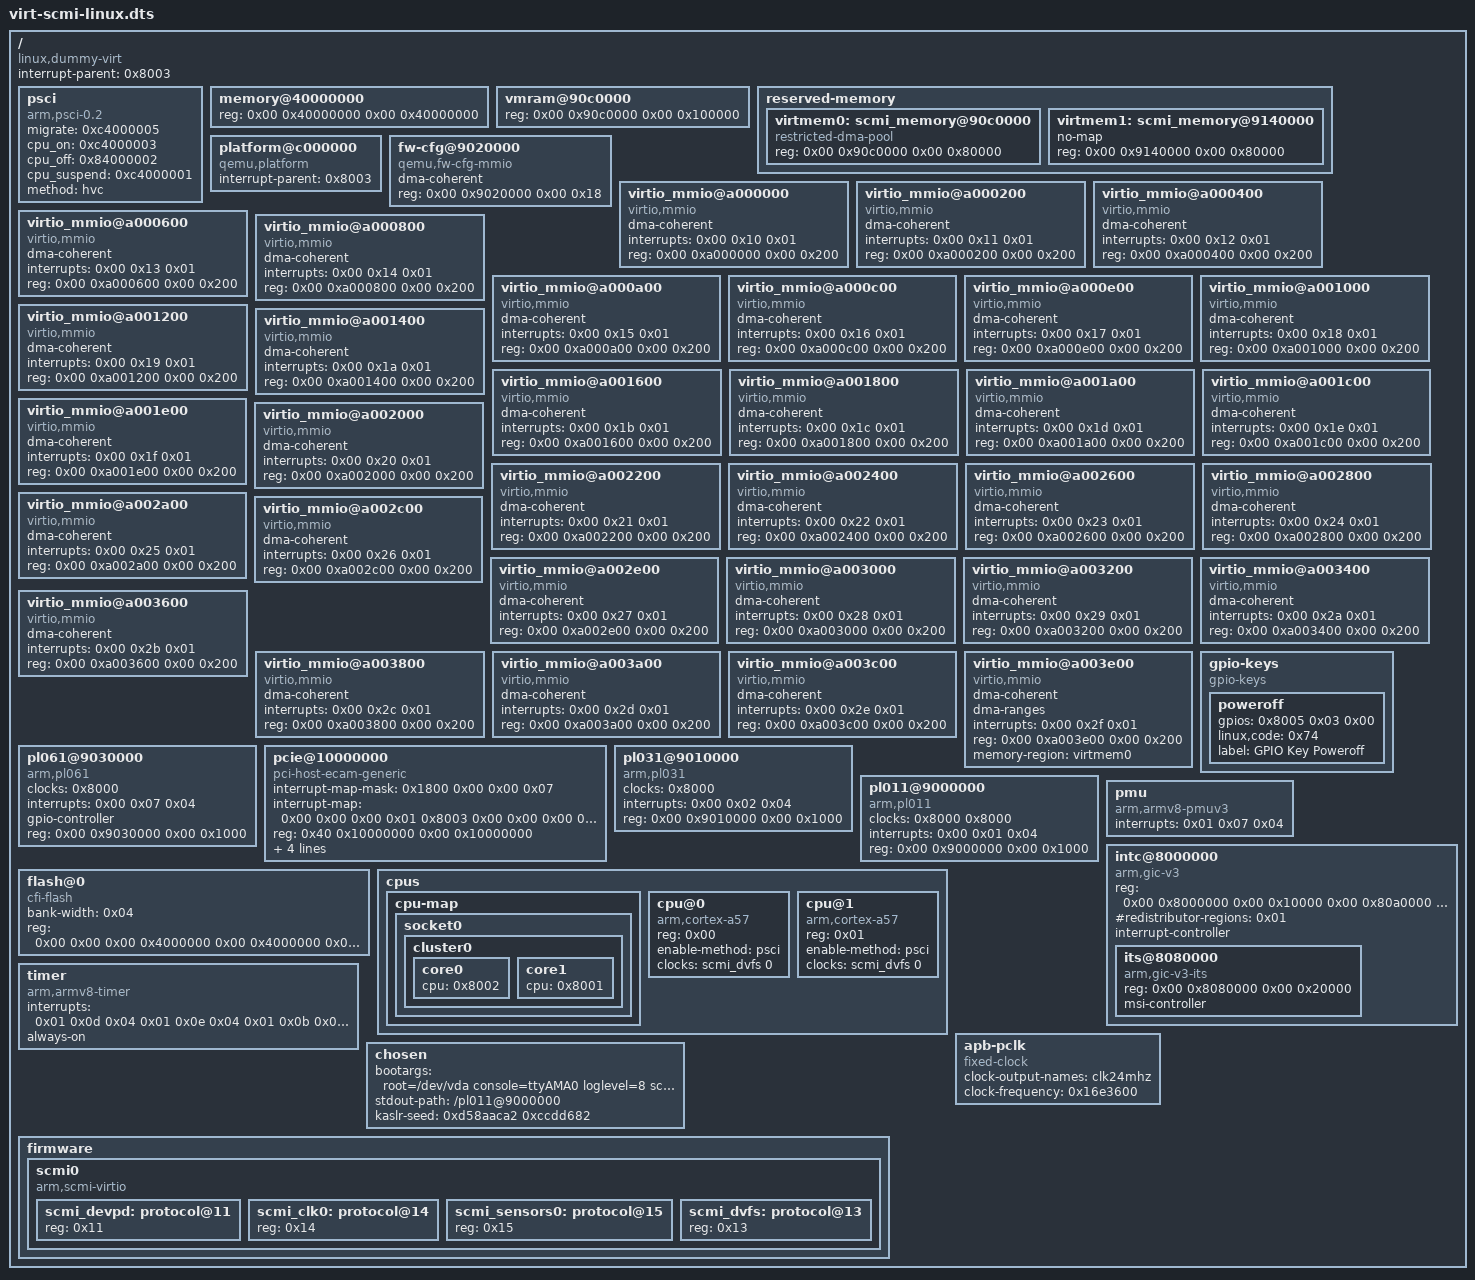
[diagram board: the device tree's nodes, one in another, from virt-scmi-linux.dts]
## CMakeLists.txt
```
# SPDX-License-Identifier: Apache-2.0

cmake_minimum_required(VERSION 3.13.1)

find_package(Zephyr REQUIRED HINTS $ENV{ZEPHYR_BASE})

target_sources(app PRIVATE src/main.c)

target_link_libraries(app PRIVATE arch-zephyr)

add_subdirectory("src/SCP-firmware" EXCLUDE_FROM_ALL)
```

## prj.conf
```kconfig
CONFIG_ASSERT=y
CONFIG_ASSERT_LEVEL=2
CONFIG_CMSIS_RTOS_V2=y
CONFIG_NUM_PREEMPT_PRIORITIES=56

CONFIG_HEAP_MEM_POOL_SIZE=131072
CONFIG_CMSIS_V2_MEM_SLAB_MAX_DYNAMIC_SIZE=131072
#CONFIG_MINIMAL_LIBC_MALLOC_ARENA_SIZE=524288
CONFIG_MINIMAL_LIBC_MALLOC_ARENA_SIZE=262144

CONFIG_THREAD_NAME=y
CONFIG_THREAD_STACK_INFO=y
CONFIG_THREAD_MONITOR=y
CONFIG_INIT_STACKS=y
CONFIG_POLL=y
CONFIG_SCHED_SCALABLE=y
CONFIG_SYS_CLOCK_TICKS_PER_SEC=1000

CONFIG_CMSIS_V2_THREAD_MAX_STACK_SIZE=131072
CONFIG_CMSIS_V2_THREAD_DYNAMIC_STACK_SIZE=131072
CONFIG_CMSIS_V2_THREAD_DYNAMIC_MAX_COUNT=8

CONFIG_OPENAMP=y
CONFIG_LIBMETAL=y
CONFIG_LOG=y
CONFIG_LOG_MODE_IMMEDIATE=y
CONFIG_LOG_DEFAULT_LEVEL=4

CONFIG_VIRTIO=y
CONFIG_VIRTIO_MMIO=y

#Use when nosecure firmware
#CONFIG_ARMV8_A_NS=y

CONFIG_HAVE_CUSTOM_LINKER_SCRIPT=y
CONFIG_CUSTOM_LINKER_SCRIPT="linker_arm64_reserved.ld"
```

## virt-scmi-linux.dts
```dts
/dts-v1/;

/ {
	interrupt-parent = < 0x8003 >;
	#size-cells = < 0x02 >;
	#address-cells = < 0x02 >;
	compatible = "linux,dummy-virt";

	psci {
		migrate = < 0xc4000005 >;
		cpu_on = < 0xc4000003 >;
		cpu_off = < 0x84000002 >;
		cpu_suspend = < 0xc4000001 >;
		method = "hvc";
		compatible = "arm,psci-0.2\0arm,psci";
	};

	memory@40000000 {
		reg = < 0x00 0x40000000 0x00 0x40000000 >;
		device_type = "memory";
	};

	vmram@90c0000 {
		status = "okay";
		reg = < 0x00 0x90c0000 0x00 0x100000 >;
		device_type = "memory";
	};

	reserved-memory {
		#address-cells = <2>;
		#size-cells = <2>;
		ranges;

		virtmem0: scmi_memory@90c0000 {
			compatible = "restricted-dma-pool";
			reg = < 0x00 0x90c0000 0x00 0x80000 >;
		};
		virtmem1: scmi_memory@9140000 {
			no-map;
			reg = < 0x00 0x9140000 0x00 0x80000 >;
		};
	};

	platform@c000000 {
		interrupt-parent = < 0x8003 >;
		ranges = < 0x00 0x00 0xc000000 0x2000000 >;
		#address-cells = < 0x01 >;
		#size-cells = < 0x01 >;
		compatible = "qemu,platform\0simple-bus";
	};

	fw-cfg@9020000 {
		dma-coherent;
		reg = < 0x00 0x9020000 0x00 0x18 >;
		compatible = "qemu,fw-cfg-mmio";
	};

	virtio_mmio@a000000 {
		dma-coherent;
		interrupts = < 0x00 0x10 0x01 >;
		reg = < 0x00 0xa000000 0x00 0x200 >;
		compatible = "virtio,mmio";
	};

	virtio_mmio@a000200 {
		dma-coherent;
		interrupts = < 0x00 0x11 0x01 >;
		reg = < 0x00 0xa000200 0x00 0x200 >;
		compatible = "virtio,mmio";
	};

	virtio_mmio@a000400 {
		dma-coherent;
		interrupts = < 0x00 0x12 0x01 >;
		reg = < 0x00 0xa000400 0x00 0x200 >;
		compatible = "virtio,mmio";
	};

	virtio_mmio@a000600 {
		dma-coherent;
		interrupts = < 0x00 0x13 0x01 >;
		reg = < 0x00 0xa000600 0x00 0x200 >;
		compatible = "virtio,mmio";
	};

	virtio_mmio@a000800 {
		dma-coherent;
		interrupts = < 0x00 0x14 0x01 >;
		reg = < 0x00 0xa000800 0x00 0x200 >;
		compatible = "virtio,mmio";
	};

	virtio_mmio@a000a00 {
		dma-coherent;
		interrupts = < 0x00 0x15 0x01 >;
		reg = < 0x00 0xa000a00 0x00 0x200 >;
		compatible = "virtio,mmio";
	};

	virtio_mmio@a000c00 {
		dma-coherent;
		interrupts = < 0x00 0x16 0x01 >;
		reg = < 0x00 0xa000c00 0x00 0x200 >;
		compatible = "virtio,mmio";
	};

	virtio_mmio@a000e00 {
		dma-coherent;
		interrupts = < 0x00 0x17 0x01 >;
		reg = < 0x00 0xa000e00 0x00 0x200 >;
		compatible = "virtio,mmio";
	};

	virtio_mmio@a001000 {
		dma-coherent;
		interrupts = < 0x00 0x18 0x01 >;
		reg = < 0x00 0xa001000 0x00 0x200 >;
		compatible = "virtio,mmio";
	};

	virtio_mmio@a001200 {
		dma-coherent;
		interrupts = < 0x00 0x19 0x01 >;
		reg = < 0x00 0xa001200 0x00 0x200 >;
		compatible = "virtio,mmio";
	};

	virtio_mmio@a001400 {
		dma-coherent;
		interrupts = < 0x00 0x1a 0x01 >;
		reg = < 0x00 0xa001400 0x00 0x200 >;
		compatible = "virtio,mmio";
	};

	virtio_mmio@a001600 {
		dma-coherent;
		interrupts = < 0x00 0x1b 0x01 >;
		reg = < 0x00 0xa001600 0x00 0x200 >;
		compatible = "virtio,mmio";
	};

	virtio_mmio@a001800 {
		dma-coherent;
		interrupts = < 0x00 0x1c 0x01 >;
		reg = < 0x00 0xa001800 0x00 0x200 >;
		compatible = "virtio,mmio";
	};

	virtio_mmio@a001a00 {
		dma-coherent;
		interrupts = < 0x00 0x1d 0x01 >;
		reg = < 0x00 0xa001a00 0x00 0x200 >;
		compatible = "virtio,mmio";
	};

	virtio_mmio@a001c00 {
		dma-coherent;
		interrupts = < 0x00 0x1e 0x01 >;
		reg = < 0x00 0xa001c00 0x00 0x200 >;
		compatible = "virtio,mmio";
	};

	virtio_mmio@a001e00 {
		dma-coherent;
		interrupts = < 0x00 0x1f 0x01 >;
		reg = < 0x00 0xa001e00 0x00 0x200 >;
		compatible = "virtio,mmio";
	};

	virtio_mmio@a002000 {
		dma-coherent;
		interrupts = < 0x00 0x20 0x01 >;
		reg = < 0x00 0xa002000 0x00 0x200 >;
		compatible = "virtio,mmio";
	};

	virtio_mmio@a002200 {
		dma-coherent;
		interrupts = < 0x00 0x21 0x01 >;
		reg = < 0x00 0xa002200 0x00 0x200 >;
		compatible = "virtio,mmio";
	};

	virtio_mmio@a002400 {
		dma-coherent;
		interrupts = < 0x00 0x22 0x01 >;
		reg = < 0x00 0xa002400 0x00 0x200 >;
		compatible = "virtio,mmio";
	};

	virtio_mmio@a002600 {
		dma-coherent;
		interrupts = < 0x00 0x23 0x01 >;
		reg = < 0x00 0xa002600 0x00 0x200 >;
		compatible = "virtio,mmio";
	};

	virtio_mmio@a002800 {
		dma-coherent;
		interrupts = < 0x00 0x24 0x01 >;
		reg = < 0x00 0xa002800 0x00 0x200 >;
		compatible = "virtio,mmio";
	};

	virtio_mmio@a002a00 {
		dma-coherent;
		interrupts = < 0x00 0x25 0x01 >;
		reg = < 0x00 0xa002a00 0x00 0x200 >;
		compatible = "virtio,mmio";
	};

	virtio_mmio@a002c00 {
		dma-coherent;
		interrupts = < 0x00 0x26 0x01 >;
		reg = < 0x00 0xa002c00 0x00 0x200 >;
		compatible = "virtio,mmio";
	};

	virtio_mmio@a002e00 {
		dma-coherent;
		interrupts = < 0x00 0x27 0x01 >;
		reg = < 0x00 0xa002e00 0x00 0x200 >;
		compatible = "virtio,mmio";
	};

	virtio_mmio@a003000 {
		dma-coherent;
		interrupts = < 0x00 0x28 0x01 >;
		reg = < 0x00 0xa003000 0x00 0x200 >;
		compatible = "virtio,mmio";
	};

	virtio_mmio@a003200 {
		dma-coherent;
		interrupts = < 0x00 0x29 0x01 >;
		reg = < 0x00 0xa003200 0x00 0x200 >;
		compatible = "virtio,mmio";
	};

	virtio_mmio@a003400 {
		dma-coherent;
		interrupts = < 0x00 0x2a 0x01 >;
		reg = < 0x00 0xa003400 0x00 0x200 >;
		compatible = "virtio,mmio";
	};

	virtio_mmio@a003600 {
		dma-coherent;
		interrupts = < 0x00 0x2b 0x01 >;
		reg = < 0x00 0xa003600 0x00 0x200 >;
		compatible = "virtio,mmio";
	};

	virtio_mmio@a003800 {
		dma-coherent;
		interrupts = < 0x00 0x2c 0x01 >;
		reg = < 0x00 0xa003800 0x00 0x200 >;
		compatible = "virtio,mmio";
	};

	virtio_mmio@a003a00 {
		dma-coherent;
		interrupts = < 0x00 0x2d 0x01 >;
		reg = < 0x00 0xa003a00 0x00 0x200 >;
		compatible = "virtio,mmio";
	};

	virtio_mmio@a003c00 {
		dma-coherent;
		interrupts = < 0x00 0x2e 0x01 >;
		reg = < 0x00 0xa003c00 0x00 0x200 >;
		compatible = "virtio,mmio";
	};

	virtio_mmio@a003e00 {
		dma-coherent;
		dma-ranges;
		interrupts = < 0x00 0x2f 0x01 >;
		reg = < 0x00 0xa003e00 0x00 0x200 >;
		compatible = "virtio,mmio";
		memory-region = <&virtmem0>;
	};

	gpio-keys {
		#address-cells = < 0x01 >;
		#size-cells = < 0x00 >;
		compatible = "gpio-keys";

		poweroff {
			gpios = < 0x8005 0x03 0x00 >;
			linux,code = < 0x74 >;
			label = "GPIO Key Poweroff";
		};
	};

	pl061@9030000 {
		phandle = < 0x8005 >;
		clock-names = "apb_pclk";
		clocks = < 0x8000 >;
		interrupts = < 0x00 0x07 0x04 >;
		gpio-controller;
		#gpio-cells = < 0x02 >;
		compatible = "arm,pl061\0arm,primecell";
		reg = < 0x00 0x9030000 0x00 0x1000 >;
	};

	pcie@10000000 {
		interrupt-map-mask = < 0x1800 0x00 0x00 0x07 >;
		interrupt-map = < 0x00 0x00 0x00 0x01 0x8003 0x00 0x00 0x00 0x03 0x04 0x00 0x00 0x00 0x02 0x8003 0x00 0x00 0x00 0x04 0x04 0x00 0x00 0x00 0x03 0x8003 0x00 0x00 0x00 0x05 0x04 0x00 0x00 0x00 0x04 0x8003 0x00 0x00 0x00 0x06 0x04 0x800 0x00 0x00 0x01 0x8003 0x00 0x00 0x00 0x04 0x04 0x800 0x00 0x00 0x02 0x8003 0x00 0x00 0x00 0x05 0x04 0x800 0x00 0x00 0x03 0x8003 0x00 0x00 0x00 0x06 0x04 0x800 0x00 0x00 0x04 0x8003 0x00 0x00 0x00 0x03 0x04 0x1000 0x00 0x00 0x01 0x8003 0x00 0x00 0x00 0x05 0x04 0x1000 0x00 0x00 0x02 0x8003 0x00 0x00 0x00 0x06 0x04 0x1000 0x00 0x00 0x03 0x8003 0x00 0x00 0x00 0x03 0x04 0x1000 0x00 0x00 0x04 0x8003 0x00 0x00 0x00 0x04 0x04 0x1800 0x00 0x00 0x01 0x8003 0x00 0x00 0x00 0x06 0x04 0x1800 0x00 0x00 0x02 0x8003 0x00 0x00 0x00 0x03 0x04 0x1800 0x00 0x00 0x03 0x8003 0x00 0x00 0x00 0x04 0x04 0x1800 0x00 0x00 0x04 0x8003 0x00 0x00 0x00 0x05 0x04 >;
		#interrupt-cells = < 0x01 >;
		ranges = < 0x1000000 0x00 0x00 0x00 0x3eff0000 0x00 0x10000 0x2000000 0x00 0x10000000 0x00 0x10000000 0x00 0x2eff0000 0x3000000 0x80 0x00 0x80 0x00 0x80 0x00 >;
		reg = < 0x40 0x10000000 0x00 0x10000000 >;
		msi-parent = < 0x8004 >;
		dma-coherent;
		bus-range = < 0x00 0xff >;
		linux,pci-domain = < 0x00 >;
		#size-cells = < 0x02 >;
		#address-cells = < 0x03 >;
		device_type = "pci";
		compatible = "pci-host-ecam-generic";
	};

	pl031@9010000 {
		clock-names = "apb_pclk";
		clocks = < 0x8000 >;
		interrupts = < 0x00 0x02 0x04 >;
		reg = < 0x00 0x9010000 0x00 0x1000 >;
		compatible = "arm,pl031\0arm,primecell";
	};

	pl011@9000000 {
		clock-names = "uartclk\0apb_pclk";
		clocks = < 0x8000 0x8000 >;
		interrupts = < 0x00 0x01 0x04 >;
		reg = < 0x00 0x9000000 0x00 0x1000 >;
		compatible = "arm,pl011\0arm,primecell";
	};

	pmu {
		interrupts = < 0x01 0x07 0x04 >;
		compatible = "arm,armv8-pmuv3";
	};

	intc@8000000 {
		phandle = < 0x8003 >;
		reg = < 0x00 0x8000000 0x00 0x10000 0x00 0x80a0000 0x00 0xf60000 >;
		#redistributor-regions = < 0x01 >;
		compatible = "arm,gic-v3";
		ranges;
		#size-cells = < 0x02 >;
		#address-cells = < 0x02 >;
		interrupt-controller;
		#interrupt-cells = < 0x03 >;

		its@8080000 {
			phandle = < 0x8004 >;
			reg = < 0x00 0x8080000 0x00 0x20000 >;
			msi-controller;
			compatible = "arm,gic-v3-its";
		};
	};

	flash@0 {
		bank-width = < 0x04 >;
		reg = < 0x00 0x00 0x00 0x4000000 0x00 0x4000000 0x00 0x4000000 >;
		compatible = "cfi-flash";
	};

	cpus {
		#size-cells = < 0x00 >;
		#address-cells = < 0x01 >;

		cpu-map {

			socket0 {

				cluster0 {

					core0 {
						cpu = < 0x8002 >;
					};

					core1 {
						cpu = < 0x8001 >;
					};
				};
			};
		};

		cpu@0 {
			phandle = < 0x8002 >;
			reg = < 0x00 >;
			enable-method = "psci";
			compatible = "arm,cortex-a57";
			device_type = "cpu";
			clocks = <&scmi_dvfs 0>;
		};

		cpu@1 {
			phandle = < 0x8001 >;
			reg = < 0x01 >;
			enable-method = "psci";
			compatible = "arm,cortex-a57";
			device_type = "cpu";
			clocks = <&scmi_dvfs 0>;
		};
	};

	timer {
		interrupts = < 0x01 0x0d 0x04 0x01 0x0e 0x04 0x01 0x0b 0x04 0x01 0x0a 0x04 >;
		always-on;
		compatible = "arm,armv8-timer\0arm,armv7-timer";
	};

	apb-pclk {
		phandle = < 0x8000 >;
		clock-output-names = "clk24mhz";
		clock-frequency = < 0x16e3600 >;
		#clock-cells = < 0x00 >;
		compatible = "fixed-clock";
	};

	chosen {
		bootargs = "root=/dev/vda console=ttyAMA0 loglevel=8 sched_debug nokaslr";
		stdout-path = "/pl011@9000000";
		kaslr-seed = <0xd58aaca2 0xccdd682>;
	};

	firmware {
		scmi0: scmi0 {
			compatible = "arm,scmi-virtio";
			#address-cells = <1>;
			#size-cells = <0>;

			scmi_devpd: protocol@11 {
				reg = <0x11>;
				#power-domain-cells = <1>;
			};

			scmi_clk0: protocol@14 {
				reg = <0x14>;
				#clock-cells = <1>;
			};

			scmi_sensors0: protocol@15 {
				reg = <0x15>;
				#thermal-sensor-cells = <1>;

			};

			scmi_dvfs: protocol@13 {
				reg = <0x13>;
				#clock-cells = <1>;
			};
		};
	};
};
```

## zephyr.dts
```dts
/dts-v1/;

/ {
	interrupt-parent = <0x8001>;
	#size-cells = <0x2>;
	#address-cells = <0x2>;
	compatible = "linux,dummy-virt";

	psci {
		migrate = <0xc4000005>;
		cpu_on = <0xc4000003>;
		cpu_off = <0x84000002>;
		cpu_suspend = <0xc4000001>;
		method = "hvc";
		compatible = "arm,psci-0.2", "arm,psci";
	};

	memory@40000000 {
		reg = <0x0 0x40000000 0x0 0x8000000>;
		device_type = "memory";
	};

	platform@c000000 {
		interrupt-parent = <0x8001>;
		ranges = <0x0 0x0 0xc000000 0x2000000>;
		#address-cells = <0x1>;
		#size-cells = <0x1>;
		compatible = "qemu,platform", "simple-bus";
	};

	fw-cfg@9020000 {
		dma-coherent;
		reg = <0x0 0x9020000 0x0 0x18>;
		compatible = "qemu,fw-cfg-mmio";
	};

	virtio_mmio@a000000 {
		dma-coherent;
		interrupts = <0x0 0x10 0x1>;
		reg = <0x0 0xa000000 0x0 0x200>;
		compatible = "virtio,mmio";
	};

	virtio_mmio@a000200 {
		dma-coherent;
		interrupts = <0x0 0x11 0x1>;
		reg = <0x0 0xa000200 0x0 0x200>;
		compatible = "virtio,mmio";
	};

	virtio_mmio@a000400 {
		dma-coherent;
		interrupts = <0x0 0x12 0x1>;
		reg = <0x0 0xa000400 0x0 0x200>;
		compatible = "virtio,mmio";
	};

	virtio_mmio@a000600 {
		dma-coherent;
		interrupts = <0x0 0x13 0x1>;
		reg = <0x0 0xa000600 0x0 0x200>;
		compatible = "virtio,mmio";
	};

	virtio_mmio@a000800 {
		dma-coherent;
		interrupts = <0x0 0x14 0x1>;
		reg = <0x0 0xa000800 0x0 0x200>;
		compatible = "virtio,mmio";
	};

	virtio_mmio@a000a00 {
		dma-coherent;
		interrupts = <0x0 0x15 0x1>;
		reg = <0x0 0xa000a00 0x0 0x200>;
		compatible = "virtio,mmio";
	};

	virtio_mmio@a000c00 {
		dma-coherent;
		interrupts = <0x0 0x16 0x1>;
		reg = <0x0 0xa000c00 0x0 0x200>;
		compatible = "virtio,mmio";
	};

	virtio_mmio@a000e00 {
		dma-coherent;
		interrupts = <0x0 0x17 0x1>;
		reg = <0x0 0xa000e00 0x0 0x200>;
		compatible = "virtio,mmio";
	};

	virtio_mmio@a001000 {
		dma-coherent;
		interrupts = <0x0 0x18 0x1>;
		reg = <0x0 0xa001000 0x0 0x200>;
		compatible = "virtio,mmio";
	};

	virtio_mmio@a001200 {
		dma-coherent;
		interrupts = <0x0 0x19 0x1>;
		reg = <0x0 0xa001200 0x0 0x200>;
		compatible = "virtio,mmio";
	};

	virtio_mmio@a001400 {
		dma-coherent;
		interrupts = <0x0 0x1a 0x1>;
		reg = <0x0 0xa001400 0x0 0x200>;
		compatible = "virtio,mmio";
	};

	virtio_mmio@a001600 {
		dma-coherent;
		interrupts = <0x0 0x1b 0x1>;
		reg = <0x0 0xa001600 0x0 0x200>;
		compatible = "virtio,mmio";
	};

	virtio_mmio@a001800 {
		dma-coherent;
		interrupts = <0x0 0x1c 0x1>;
		reg = <0x0 0xa001800 0x0 0x200>;
		compatible = "virtio,mmio";
	};

	virtio_mmio@a001a00 {
		dma-coherent;
		interrupts = <0x0 0x1d 0x1>;
		reg = <0x0 0xa001a00 0x0 0x200>;
		compatible = "virtio,mmio";
	};

	virtio_mmio@a001c00 {
		dma-coherent;
		interrupts = <0x0 0x1e 0x1>;
		reg = <0x0 0xa001c00 0x0 0x200>;
		compatible = "virtio,mmio";
	};

	virtio_mmio@a001e00 {
		dma-coherent;
		interrupts = <0x0 0x1f 0x1>;
		reg = <0x0 0xa001e00 0x0 0x200>;
		compatible = "virtio,mmio";
	};

	virtio_mmio@a002000 {
		dma-coherent;
		interrupts = <0x0 0x20 0x1>;
		reg = <0x0 0xa002000 0x0 0x200>;
		compatible = "virtio,mmio";
	};

	virtio_mmio@a002200 {
		dma-coherent;
		interrupts = <0x0 0x21 0x1>;
		reg = <0x0 0xa002200 0x0 0x200>;
		compatible = "virtio,mmio";
	};

	virtio_mmio@a002400 {
		dma-coherent;
		interrupts = <0x0 0x22 0x1>;
		reg = <0x0 0xa002400 0x0 0x200>;
		compatible = "virtio,mmio";
	};

	virtio_mmio@a002600 {
		dma-coherent;
		interrupts = <0x0 0x23 0x1>;
		reg = <0x0 0xa002600 0x0 0x200>;
		compatible = "virtio,mmio";
	};

	virtio_mmio@a002800 {
		dma-coherent;
		interrupts = <0x0 0x24 0x1>;
		reg = <0x0 0xa002800 0x0 0x200>;
		compatible = "virtio,mmio";
	};

	virtio_mmio@a002a00 {
		dma-coherent;
		interrupts = <0x0 0x25 0x1>;
		reg = <0x0 0xa002a00 0x0 0x200>;
		compatible = "virtio,mmio";
	};

	virtio_mmio@a002c00 {
		dma-coherent;
		interrupts = <0x0 0x26 0x1>;
		reg = <0x0 0xa002c00 0x0 0x200>;
		compatible = "virtio,mmio";
	};

	virtio_mmio@a002e00 {
		dma-coherent;
		interrupts = <0x0 0x27 0x1>;
		reg = <0x0 0xa002e00 0x0 0x200>;
		compatible = "virtio,mmio";
	};

	virtio_mmio@a003000 {
		dma-coherent;
		interrupts = <0x0 0x28 0x1>;
		reg = <0x0 0xa003000 0x0 0x200>;
		compatible = "virtio,mmio";
	};

	virtio_mmio@a003200 {
		dma-coherent;
		interrupts = <0x0 0x29 0x1>;
		reg = <0x0 0xa003200 0x0 0x200>;
		compatible = "virtio,mmio";
	};

	virtio_mmio@a003400 {
		dma-coherent;
		interrupts = <0x0 0x2a 0x1>;
		reg = <0x0 0xa003400 0x0 0x200>;
		compatible = "virtio,mmio";
	};

	virtio_mmio@a003600 {
		dma-coherent;
		interrupts = <0x0 0x2b 0x1>;
		reg = <0x0 0xa003600 0x0 0x200>;
		compatible = "virtio,mmio";
	};

	virtio_mmio@a003800 {
		dma-coherent;
		interrupts = <0x0 0x2c 0x1>;
		reg = <0x0 0xa003800 0x0 0x200>;
		compatible = "virtio,mmio";
	};

	virtio_mmio@a003a00 {
		dma-coherent;
		interrupts = <0x0 0x2d 0x1>;
		reg = <0x0 0xa003a00 0x0 0x200>;
		compatible = "virtio,mmio";
	};

	virtio_mmio@a003c00 {
		dma-coherent;
		interrupts = <0x0 0x2e 0x1>;
		reg = <0x0 0xa003c00 0x0 0x200>;
		compatible = "virtio,mmio";
	};

	virtio_mmio@a003e00 {
		dma-coherent;
		interrupts = <0x0 0x2f 0x1>;
		reg = <0x0 0xa003e00 0x0 0x200>;
		compatible = "virtio,mmio";
	};

	gpio-restart {
		secure-status = "okay";
		status = "disabled";
		gpios = <0x8003 0x1 0x0>;
		compatible = "gpio-restart";
	};

	gpio-poweroff {
		secure-status = "okay";
		status = "disabled";
		gpios = <0x8003 0x0 0x0>;
		compatible = "gpio-poweroff";
	};

	pl061@90b0000 {
		secure-status = "okay";
		status = "disabled";
		phandle = <0x8003>;
		clock-names = "apb_pclk";
		clocks = <0x8000>;
		interrupts = <0x0 0x0 0x4>;
		gpio-controller;
		#gpio-cells = <0x2>;
		compatible = "arm,pl061", "arm,primecell";
		reg = <0x0 0x90b0000 0x0 0x1000>;
	};

	gpio-keys {
		#address-cells = <0x1>;
		#size-cells = <0x0>;
		compatible = "gpio-keys";

		poweroff {
			gpios = <0x8002 0x3 0x0>;
			linux,code = <0x74>;
			label = "GPIO Key Poweroff";
		};
	};

	pl061@9030000 {
		phandle = <0x8002>;
		clock-names = "apb_pclk";
		clocks = <0x8000>;
		interrupts = <0x0 0x7 0x4>;
		gpio-controller;
		#gpio-cells = <0x2>;
		compatible = "arm,pl061", "arm,primecell";
		reg = <0x0 0x9030000 0x0 0x1000>;
	};

	pcie@10000000 {
		interrupt-map-mask = <0x1800 0x0 0x0 0x7>;
		interrupt-map = <0x0 0x0 0x0 0x1 0x8001 0x0 0x0 0x0 0x3 0x4 0x0 0x0 0x0 0x2 0x8001 0x0 0x0 0x0 0x4 0x4 0x0 0x0 0x0 0x3 0x8001 0x0 0x0 0x0 0x5 0x4 0x0 0x0 0x0 0x4 0x8001 0x0 0x0 0x0 0x6 0x4 0x800 0x0 0x0 0x1 0x8001 0x0 0x0 0x0 0x4 0x4 0x800 0x0 0x0 0x2 0x8001 0x0 0x0 0x0 0x5 0x4 0x800 0x0 0x0 0x3 0x8001 0x0 0x0 0x0 0x6 0x4 0x800 0x0 0x0 0x4 0x8001 0x0 0x0 0x0 0x3 0x4 0x1000 0x0 0x0 0x1 0x8001 0x0 0x0 0x0 0x5 0x4 0x1000 0x0 0x0 0x2 0x8001 0x0 0x0 0x0 0x6 0x4 0x1000 0x0 0x0 0x3 0x8001 0x0 0x0 0x0 0x3 0x4 0x1000 0x0 0x0 0x4 0x8001 0x0 0x0 0x0 0x4 0x4 0x1800 0x0 0x0 0x1 0x8001 0x0 0x0 0x0 0x6 0x4 0x1800 0x0 0x0 0x2 0x8001 0x0 0x0 0x0 0x3 0x4 0x1800 0x0 0x0 0x3 0x8001 0x0 0x0 0x0 0x4 0x4 0x1800 0x0 0x0 0x4 0x8001 0x0 0x0 0x0 0x5 0x4>;
		#interrupt-cells = <0x1>;
		ranges = <0x1000000 0x0 0x0 0x0 0x3eff0000 0x0 0x10000 0x2000000 0x0 0x10000000 0x0 0x10000000 0x0 0x2eff0000 0x3000000 0x80 0x0 0x80 0x0 0x80 0x0>;
		reg = <0x40 0x10000000 0x0 0x10000000>;
		dma-coherent;
		bus-range = <0x0 0xff>;
		linux,pci-domain = <0x0>;
		#size-cells = <0x2>;
		#address-cells = <0x3>;
		device_type = "pci";
		compatible = "pci-host-ecam-generic";
	};

	pl031@9010000 {
		clock-names = "apb_pclk";
		clocks = <0x8000>;
		interrupts = <0x0 0x2 0x4>;
		reg = <0x0 0x9010000 0x0 0x1000>;
		compatible = "arm,pl031", "arm,primecell";
	};

	pl011@9040000 {
		secure-status = "okay";
		status = "disabled";
		clock-names = "uartclk", "apb_pclk";
		clocks = <0x8000 0x8000>;
		interrupts = <0x0 0x8 0x4>;
		reg = <0x0 0x9040000 0x0 0x1000>;
		compatible = "arm,pl011", "arm,primecell";
	};

	secram@e000000 {
		secure-status = "okay";
		status = "disabled";
		reg = <0x0 0xe000000 0x0 0x1000000>;
		device_type = "memory";
	};

	pl011@9000000 {
		clock-names = "uartclk", "apb_pclk";
		clocks = <0x8000 0x8000>;
		interrupts = <0x0 0x1 0x4>;
		reg = <0x0 0x9000000 0x0 0x1000>;
		compatible = "arm,pl011", "arm,primecell";
	};

	pmu {
		interrupts = <0x1 0x7 0x4>;
		compatible = "arm,armv8-pmuv3";
	};

	intc@8000000 {
		phandle = <0x8001>;
		reg = <0x0 0x8000000 0x0 0x10000 0x0 0x80a0000 0x0 0xf60000>;
		#redistributor-regions = <0x1>;
		compatible = "arm,gic-v3";
		ranges;
		#size-cells = <0x2>;
		#address-cells = <0x2>;
		interrupt-controller;
		#interrupt-cells = <0x3>;
	};

	flash@0 {
		bank-width = <0x4>;
		reg = <0x0 0x4000000 0x0 0x4000000>;
		compatible = "cfi-flash";
	};

	secflash@0 {
		secure-status = "okay";
		status = "disabled";
		bank-width = <0x4>;
		reg = <0x0 0x0 0x0 0x4000000>;
		compatible = "cfi-flash";
	};

	cpus {
		#size-cells = <0x0>;
		#address-cells = <0x1>;

		cpu@0 {
			reg = <0x0>;
			compatible = "arm,cortex-a53";
			device_type = "cpu";
		};
	};

	timer {
		interrupts = <0x1 0xd 0x4 0x1 0xe 0x4 0x1 0xb 0x4 0x1 0xa 0x4>;
		always-on;
		compatible = "arm,armv8-timer", "arm,armv7-timer";
	};

	apb-pclk {
		phandle = <0x8000>;
		clock-output-names = "clk24mhz";
		clock-frequency = <0x16e3600>;
		#clock-cells = <0x0>;
		compatible = "fixed-clock";
	};

	secure-chosen {
		stdout-path = "/pl011@9040000";
		kaslr-seed = <0x1f42147f 0x7d6bc4ce>;
	};

	chosen {
		stdout-path = "/pl011@9000000";
		kaslr-seed = <0x12c281c5 0xa29074e6>;
	};
};
```

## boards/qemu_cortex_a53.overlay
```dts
/*
 * Copyright (c) 2019 Linaro Limited
 *
 * SPDX-License-Identifier: Apache-2.0
 */
#include <dt-bindings/interrupt-controller/arm-gic.h>

/ {
	reserved-memory {
		compatible = "reserved-memory";
		#address-cells = <1>;
		#size-cells = <1>;
		status = "okay";
		ranges;

		vmram0: vmram@90c0000 {
			status = "okay";
			reg = < 0x90c0000 0x80000 >;
			device_type = "memory";
			label = "vmram0";
		};

		vmram1: vmram@90d0000 {
			status = "okay";
			reg = < 0x9140000 0x80000 >;
			device_type = "memory";
			label = "vmram1";
		};
	};


	virtio_mmio0: virtio_mmio@a003e00 {
		dma-coherent;
		compatible = "virtio-mmio";
		reg = <0xa003e00 0x200>;
		status = "okay";
		interrupts = <GIC_SPI 0x2f IRQ_TYPE_EDGE IRQ_DEFAULT_PRIORITY>;
		interrupt-parent = <&gic>;
		label = "virtio_mmio0";
		memory-region = <&vmram0>;
		device-mode;
	};

	virtio_mmio1: virtio_mmio@a003c00 {
		dma-coherent;
		compatible = "virtio-mmio";
		reg = <0xa003c00 0x200>;
		status = "okay";
		interrupts = <GIC_SPI 0x2e IRQ_TYPE_EDGE IRQ_DEFAULT_PRIORITY>;
		interrupt-parent = <&gic>;
		label = "virtio_mmio1";
		memory-region = <&vmram1>;
		device-mode;
	};

};
```

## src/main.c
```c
/*
 * Copyright (c) 2012-2014 Wind River Systems, Inc.
 *
 * SPDX-License-Identifier: Apache-2.0
 */

#include <arch_main.h>

#include <zephyr.h>
#include <sys/printk.h>


void main(void)
{
	printk("Starting virtio scmi backend %s\n", CONFIG_BOARD);

	scmi_arch_init();

}
```
